# STM32H7P5xx register map
File version: 1.0
Registers are 32-bit, read-write, reset 0x0 unless marked. A register's access mark holds for its fields unless they carry their own. Offsets are from the block's base; [hi:lo] are bit positions.

## ADF1 — Audio Digital Filter (ADF)
Base 0x4002F000
0x00 GCR — ADF Global Control Register
  [0] TRGO — Trigger output control
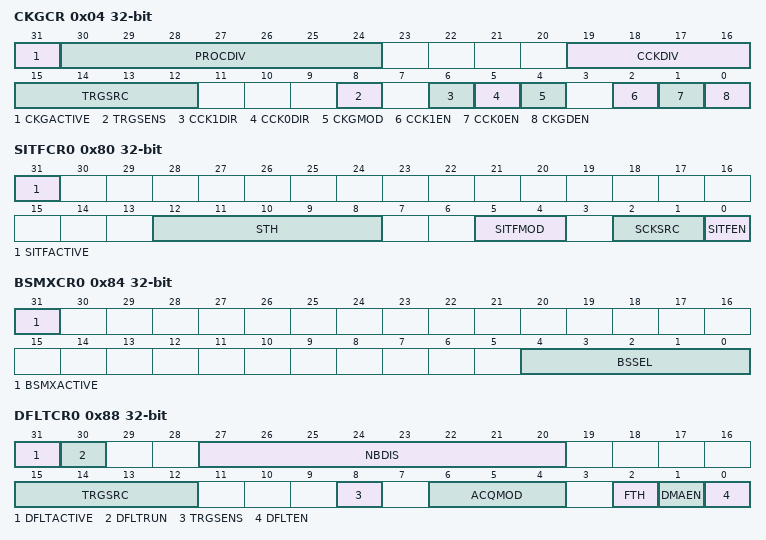
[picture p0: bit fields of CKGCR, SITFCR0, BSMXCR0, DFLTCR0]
0x04 CKGCR — ADF Clock Generator Control Register
  [31] CKGACTIVE — Clock generator active flag
  [30:24] PROCDIV — Divider to control the serial interface clock
  [19:16] CCKDIV — Divider to control the ADF_CCK clock
  [15:12] TRGSRC — Digital Filter trigger signal selection
  [8] TRGSENS — CKGEN trigger sensitivity selection
  [6] CCK1DIR — CCK1 clock direction
  [5] CCK0DIR — CCK0 clock direction
  [4] CKGMOD — Clock generator mode
  [2] CCK1EN — CCK1 clock enable
  [1] CCK0EN — CCK0 clock enable
  [0] CKGDEN — CKGEN dividers enable
0x80 SITFCR0 — ADF Serial Interface Control Register
  [31] SITFACTIVE — Serial interface active flag
  [12:8] STH — Manchester symbol threshold / SPI threshold
  [5:4] SITFMOD — Serial interface type
  [2:1] SCKSRC — Serial clock source
  [0] SITFEN — Serial interface enable
0x84 BSMXCR0 — ADF Bitstream Matrix Control Register
  [31] BSMXACTIVE — Bitstream matrix active flag
  [4:0] BSSEL — Bitstream selection
0x88 DFLTCR0 — ADF Digital Filter Control Register
  [31] DFLTACTIVE — Digital filter active flag
  [30] DFLTRUN — Digital filter run status flag
  [27:20] NBDIS — Number of samples to be discarded
  [15:12] TRGSRC — Digital filter trigger signal selection
  [8] TRGSENS — Digital filter trigger sensitivity selection
  [6:4] ACQMOD — Digital filter trigger mode
  [2] FTH — RXFIFO threshold selection
  [1] DMAEN — DMA request enable
  [0] DFLTEN — Digital filter enable
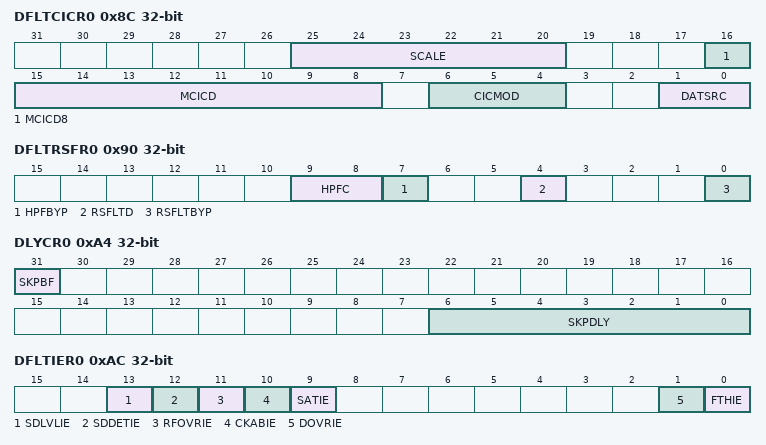
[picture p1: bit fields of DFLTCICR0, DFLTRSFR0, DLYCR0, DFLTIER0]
0x8C DFLTCICR0 — ADF MCIC Configuration Register
  [25:20] SCALE — Scaling factor selection
  [16] MCICD8 — CIC decimation ratio selection
  [15:8] MCICD — CIC decimation ratio selection
  [6:4] CICMOD — Select the CIC order
  [1:0] DATSRC — Source data for the digital filter
0x90 DFLTRSFR0 — ADF Reshape Filter Configuration Register
  [9:8] HPFC — High-pass filter cut-off frequency
  [7] HPFBYP — High-pass filter bypass
  [4] RSFLTD — Reshape filter decimation ratio
  [0] RSFLTBYP — Reshape filter bypass
0xA4 DLYCR0 — ADF Delay Control Register
  [31] SKPBF — Skip Busy Flag
  [6:0] SKPDLY — Delay to apply to a bitstream
0xAC DFLTIER0 — ADF DFLT Interrupt Enable Register
  [13] SDLVLIE — Sound level value ready interrupt enable
  [12] SDDETIE — Sound activity detection interrupt enable
  [11] RFOVRIE — Reshape filter overrun interrupt enable
  [10] CKABIE — Clock absence detection interrupt enable
  [9] SATIE — Saturation detection interrupt enable
  [1] DOVRIE — Data overflow interrupt enable
  [0] FTHIE — RXFIFO threshold interrupt enable
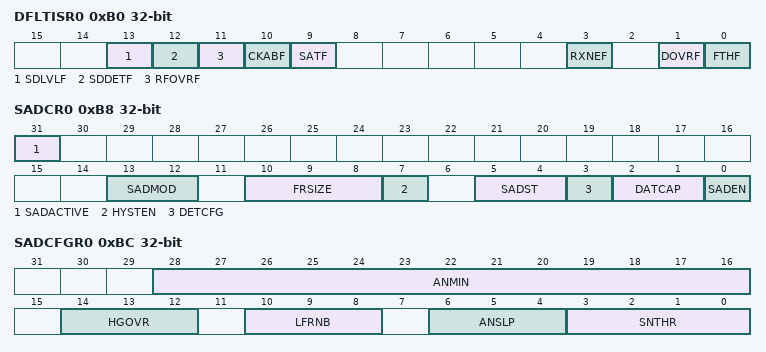
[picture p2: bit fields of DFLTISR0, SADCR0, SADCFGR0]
0xB0 DFLTISR0 — ADF DFLT Interrupt Status Register
  [13] SDLVLF — Sound level value ready flag
  [12] SDDETF — Sound activity detection flag
  [11] RFOVRF — Reshape filter overrun detection flag
  [10] CKABF — Clock absence detection flag
  [9] SATF — Saturation detection flag
  [3] RXNEF — RXFIFO not empty flag
  [1] DOVRF — Data overflow flag
  [0] FTHF — RXFIFO threshold flag
0xB8 SADCR0 — ADF SAD Control Register
  [31] SADACTIVE — SAD active flag
  [13:12] SADMOD — SAD working mode
  [10:8] FRSIZE — Frame size
  [7] HYSTEN — Hysteresis enable
  [5:4] SADST — SAD state
  [3] DETCFG — Sound trigger event configuration
  [2:1] DATCAP — Data capture mode
  [0] SADEN — Sound activity detector enable
0xBC SADCFGR0 — ADF SAD Configuration Register
  [28:16] ANMIN — Minimum noise level
  [14:12] HGOVR — Hangover time window
  [10:8] LFRNB — Number of learning frames
  [6:4] ANSLP — Ambiant noise slope control
  [3:0] SNTHR — Signal to noise threshold
0xC0 SADSDLVR0 ro — ADF SAD Sound Level Register
  [14:0] SDLVL — Short term sound level
0xC4 SADANLVR0 ro — ADF SAD Ambient Noise Level Register
  [14:0] ANLVL — Ambiant noise level estimation
0xF0 DFLTDR0 ro — ADF Digital Filter Data Register
  [31:8] DR — Data processed by digital filter
